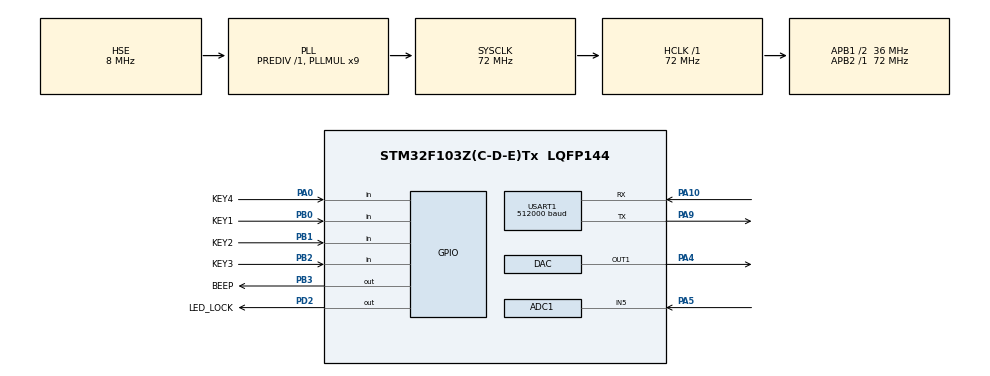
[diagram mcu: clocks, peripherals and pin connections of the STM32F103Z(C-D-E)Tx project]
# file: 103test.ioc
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ADC1.Channel-0\#ChannelRegularConversion=ADC_CHANNEL_5
ADC1.NbrOfConversionFlag=1
ADC1.Rank-0\#ChannelRegularConversion=1
ADC1.SamplingTime-0\#ChannelRegularConversion=ADC_SAMPLETIME_239CYCLES_5
ADC1.master=1
DAC.DAC_OutputBuffer=DAC_OUTPUTBUFFER_DISABLE
DAC.DAC_Trigger=DAC_TRIGGER_T2_TRGO
Dma.DAC_CH1.0.Direction=DMA_MEMORY_TO_PERIPH
Dma.DAC_CH1.0.Instance=DMA2_Channel3
Dma.DAC_CH1.0.MemDataAlignment=DMA_MDATAALIGN_HALFWORD
Dma.DAC_CH1.0.MemInc=DMA_MINC_ENABLE
Dma.DAC_CH1.0.Mode=DMA_CIRCULAR
Dma.DAC_CH1.0.PeriphDataAlignment=DMA_PDATAALIGN_HALFWORD
Dma.DAC_CH1.0.PeriphInc=DMA_PINC_DISABLE
Dma.DAC_CH1.0.Priority=DMA_PRIORITY_LOW
Dma.Request0=DAC_CH1
Mcu.Family=STM32F1
Mcu.Name=STM32F103Z(C-D-E)Tx
Mcu.Package=LQFP144
NVIC.DMA2_Channel3_IRQn=true\:0\:0\:false\:false\:true\:false\:true
NVIC.PriorityGroup=NVIC_PRIORITYGROUP_4
NVIC.USART1_IRQn=true\:0\:0\:false\:false\:true\:true\:true
OSC_IN.Mode=HSE-External-Oscillator
OSC_IN.Signal=RCC_OSC_IN
OSC_OUT.Mode=HSE-External-Oscillator
OSC_OUT.Signal=RCC_OSC_OUT
PA0-WKUP.GPIO_Label=KEY4
PA0-WKUP.Signal=GPIO_Input
PA10.Mode=Asynchronous
PA10.Signal=USART1_RX
PA4.Signal=COMP_DAC1_group
PA5.Signal=ADCx_IN5
PA9.Mode=Asynchronous
PA9.Signal=USART1_TX
PB0.GPIO_Label=KEY1
PB0.Signal=GPIO_Input
PB1.GPIO_Label=KEY2
PB1.Signal=GPIO_Input
PB2.GPIO_Label=KEY3
PB2.Signal=GPIO_Input
PB3.GPIO_Label=BEEP
PB3.Signal=GPIO_Output
PD2.GPIO_Label=LED_LOCK
PD2.Signal=GPIO_Output
ProjectManager.HeapSize=0x200
ProjectManager.StackSize=0x400
ProjectManager.TargetToolchain=MDK-ARM V5
RCC.ADCPresc=RCC_ADCPCLK2_DIV6
RCC.AHBFreq_Value=72000000
RCC.APB1CLKDivider=RCC_HCLK_DIV2
RCC.APB1Freq_Value=36000000
RCC.APB1TimFreq_Value=72000000
RCC.APB2Freq_Value=72000000
RCC.APB2TimFreq_Value=72000000
RCC.HCLKFreq_Value=72000000
RCC.PLLMUL=RCC_PLL_MUL9
RCC.PLLSourceVirtual=RCC_PLLSOURCE_HSE
RCC.SYSCLKFreq_VALUE=72000000
RCC.SYSCLKSource=RCC_SYSCLKSOURCE_PLLCLK
RCC.USBFreq_Value=72000000
SH.ADCx_IN5.0=ADC1_IN5,IN5
SH.COMP_DAC1_group.0=DAC_OUT1,DAC_OUT1
TIM2.AutoReloadPreload=TIM_AUTORELOAD_PRELOAD_ENABLE
TIM2.Period=7199
TIM2.TIM_MasterOutputTrigger=TIM_TRGO_UPDATE
USART1.BaudRate=512000
USART1.VirtualMode=VM_ASYNC
VP_SYS_VS_ND.Mode=No_Debug
VP_TIM2_VS_ClockSourceINT.Mode=Internal
board=custom

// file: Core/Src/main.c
/* USER CODE BEGIN Header */
/**
 ******************************************************************************
 * @file           : main.c
 * @brief          : Main program body
 ******************************************************************************
 * @attention
 *
 * <h2><center>&copy; Copyright (c) 2022 STMicroelectronics.
 * All rights reserved.</center></h2>
 *
 * This software component is licensed by ST under BSD 3-Clause license,
 * the "License"; You may not use this file except in compliance with the
 * License. You may obtain a copy of the License at:
 *                        opensource.org/licenses/BSD-3-Clause
 *
 ******************************************************************************
 */
/* USER CODE END Header */
#include "main.h"
#include "adc.h"
#include "dac.h"
#include "dma.h"
#include "tim.h"
#include "usart.h"
#include "gpio.h"

/* USER CODE BEGIN Includes */
#include "signal_generator_system.h"
#include "bll_beep.h"
#include "ui.h"

/* USER CODE END Includes */

/* USER CODE BEGIN PD */

//#define UART_SEND_ADC_DATA

/* USER CODE END PD */

/* USER CODE BEGIN PV */

// u8 UART_LED_Flag = 0;   // UART命令接收指示灯状�?

/* USER CODE END PV */

void SystemClock_Config(void);
/* USER CODE BEGIN PFP */

// void LED_UART_Rx_Command_State_Task(void);

/* USER CODE END PFP */

int main(void)
{
  /* USER CODE BEGIN 1 */
  // PSignal_Generator_Type pSG = Get_Signal_Generator_Index();
  /* USER CODE END 1 */

  /* MCU Configuration--------------------------------------------------------*/

  /* Reset of all peripherals, Initializes the Flash interface and the Systick. */
  HAL_Init();

  /* Configure the system clock */
  SystemClock_Config();

  /* Initialize all configured peripherals */
  MX_GPIO_Init();
  MX_DMA_Init();
  MX_DAC_Init();
  MX_ADC1_Init();
  MX_TIM2_Init();
  MX_USART1_UART_Init();
  /* USER CODE BEGIN 2 */

  // 初始化相关参�? 打开控制DAC定时器中�? �? 使能DAC模块
  gpSignal_Generator->Init();

  // �?启串口接收中�?
  gpCommunity->Init();

  // 初始LCD并显示界�?
  gpUI->Init();

  /* USER CODE END 2 */

  /* Infinite loop */
  /* USER CODE BEGIN WHILE */

  while (1)
  {
    gpKEY->Task();      // 按键逻辑�?�?
    gpBEEP->Task();     // 蜂鸣器任�?
    gpUI->UpdateTask(); // 界面刷新任务

    gpCommunity->SendDataTask();       // 实时数据发�?�任�?
    gpCommunity->ReceiveCommandTask(); // 命令接收�?查任�?

    /* USER CODE END WHILE */

  }
}

void SystemClock_Config(void)
{
  RCC_OscInitTypeDef RCC_OscInitStruct = {0};
  RCC_ClkInitTypeDef RCC_ClkInitStruct = {0};
  RCC_PeriphCLKInitTypeDef PeriphClkInit = {0};

  /** Initializes the RCC Oscillators according to the specified parameters
   * in the RCC_OscInitTypeDef structure.
   */
  RCC_OscInitStruct.OscillatorType = RCC_OSCILLATORTYPE_HSE;
  RCC_OscInitStruct.HSEState = RCC_HSE_ON;
  RCC_OscInitStruct.HSEPredivValue = RCC_HSE_PREDIV_DIV1;
  RCC_OscInitStruct.HSIState = RCC_HSI_ON;
  RCC_OscInitStruct.PLL.PLLState = RCC_PLL_ON;
  RCC_OscInitStruct.PLL.PLLSource = RCC_PLLSOURCE_HSE;
  RCC_OscInitStruct.PLL.PLLMUL = RCC_PLL_MUL9;
  if (HAL_RCC_OscConfig(&RCC_OscInitStruct) != HAL_OK)
  {
    Error_Handler();
  }
  /** Initializes the CPU, AHB and APB buses clocks
   */
  RCC_ClkInitStruct.ClockType = RCC_CLOCKTYPE_HCLK | RCC_CLOCKTYPE_SYSCLK | RCC_CLOCKTYPE_PCLK1 | RCC_CLOCKTYPE_PCLK2;
  RCC_ClkInitStruct.SYSCLKSource = RCC_SYSCLKSOURCE_PLLCLK;
  RCC_ClkInitStruct.AHBCLKDivider = RCC_SYSCLK_DIV1;
  RCC_ClkInitStruct.APB1CLKDivider = RCC_HCLK_DIV2;
  RCC_ClkInitStruct.APB2CLKDivider = RCC_HCLK_DIV1;

  if (HAL_RCC_ClockConfig(&RCC_ClkInitStruct, FLASH_LATENCY_2) != HAL_OK)
  {
    Error_Handler();
  }
  PeriphClkInit.PeriphClockSelection = RCC_PERIPHCLK_ADC;
  PeriphClkInit.AdcClockSelection = RCC_ADCPCLK2_DIV6;
  if (HAL_RCCEx_PeriphCLKConfig(&PeriphClkInit) != HAL_OK)
  {
    Error_Handler();
  }
}

/* USER CODE BEGIN 4 */
/***************************************************/
/****************    LED部分      ******************/

// void LED_UART_Rx_Command_State_Task(void)
//{
//     if(UART_LED_Flag == 1)
//     {
//         LED_Disp(0x01);
//         if(SW_Timer_Tick[4] < HAL_GetTick())
//         {
//             LED_Disp(0x00);
//             UART_LED_Flag = 0;
//         }
//     }
//     else if(UART_LED_Flag == 2)
//     {
//         LED_Disp(0x80);
//         if(SW_Timer_Tick[4] < HAL_GetTick())
//         {
//             LED_Disp(0x00);
//             UART_LED_Flag = 0;
//         }
//     }
// }

/* USER CODE END 4 */

void Error_Handler(void)
{
  __disable_irq();
  while (1)
  {
  }
}

/************************ (C) COPYRIGHT STMicroelectronics *****END OF FILE****/
